# RL6842_IP_SVD register map
Vendor: Realtek
IP svd file
Registers are 32-bit, read-write, reset 0x0 unless marked. A register's access mark holds for its fields unless they carry their own. Offsets are from the block's base; lines under a group give offsets from that group; [hi:lo] are bit positions; {n}, {i} and the like mark numbered series; 'fields as' and 'values as' point back to an identical list; <NAME> marks a mode.

## Memory map
0x40000000 page0 size 0x100
0x40000000 page1 size 0x1200
0x40000000 page2 size 0x300
0x40000000 page3 size 0x1310
0x40000000 page4 size 0x14A4
0x40000000 page5 size 0x15AC
0x40000000 page6 size 0x1700
0x40000000 page7 size 0x800
0x40000000 page12 size 0x1300
0x40000000 page17 size 0x1800
0x40000000 page26 size 0x2620
0x40000000 txpwr_ctrl size 0xDB04
0x40100000 RSIP size 0x160
0x40100000 ipsec size 0x101C
0x40108000 hash size 0x101C
0x40118000 spi size 0xB0C
0x4011A000 i2c size 0x100
0x4011C000 SPORT size 0x984
0x4011E000 debugtimer size 0x18
0x4011F000 ECDSA size 0x204
0x41000000 otpc size 0x44
0x41000000 otpc_sec size 0x744
0x4100C000 lp_aon size 0x100
0x4100C100 regu size 0x80
0x4100C200 lp_sys size 0x100
0x4100C300 lp_pmc size 0x64
0x4100C400 xtal size 0x40
0x4100C440 pll size 0x38
0x4100C480 wlafe size 0x40
0x4100C600 memx size 0x200
0x4100CC00 iwdg size 0x14
0x4100F000 uartirda size 0x60
0x41014000 loguart size 0x78
0x41015000 ledc size 0xF8
0x41017000 audio size 0x908
0x41019000 timerpwm size 0x88
0x4101A000 gpio size 0x100
0x4101B000 rtc size 0x2C
0x4101C000 adc size 0xB4
0x4101C800 comp size 0x58
0x4101D000 thermal size 0x34
0x4101E000 captouch size 0x418
0x41020000 ipc size 0x28
0x41022100 aud size 0x30
0x42001C00 zgb size 0x28

## debugtimer
Base 0x4011E000
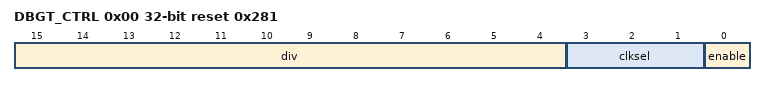
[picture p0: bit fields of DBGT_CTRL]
0x00 DBGT_CTRL reset 0x281 — debugtimer control register
  [15:4] div — The default value can used to divide 40M XTAL to 1M
  [3:1] clksel — Clock source selection 2~7: Reserved 1: Select 32K as clock source. 0: Select Xtal as clock source.
  [0] enable — Debug timer enable 1: The counter is enabled. 0: The counter is disabled.
0x04 DBGT_CRV — debugtimer count register
  [31:0] dbgt_crv — Continue to count from 0 once it's reached 32'hFFFFFFFF
0x08 DBGT_ATOM_INC ro — debugtimer atom read increase register
  [31:0] dbgt_atom_inc — Each read will increase 1 and return to the increased value to bus.
0x0C DBGT_ATOM — debugtimer atom register
  [31:0] dbgt_atom — Return the last increased value of atom counter
0x10 DBGT_SCRATCH — debugtimer scratch register
  [31:0] dbgt_scratch — Reserved for users
0x14 REG_DBGTIM_DUMMY reset 0xFFFF — Debug Timer Dummy Register

## iwdg
Base 0x4100CC00
0x00 WDG_MKEYR — WDG Magic Key Register
  [15:0] MKEY — 0x6969: enable access to register WDG_CR/WDG_RLR/WDG_WINR 0x5A5A: reload WDG counter 0x3C3C: enable WDG function
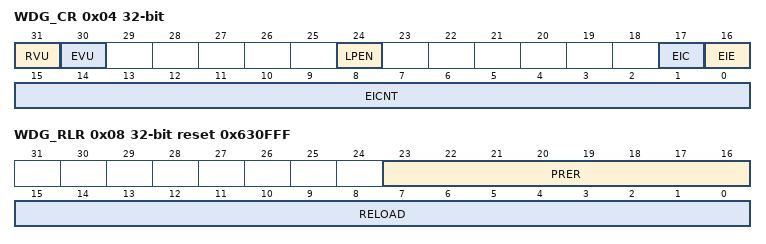
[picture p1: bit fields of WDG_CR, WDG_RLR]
0x04 WDG_CR access per field — WDG Control Regsietr
  [31] RVU ro — Watchdog counter update by reload command
  [30] EVU ro — Watchdog early interrupt function update
  [24] LPEN rw — Low power enable 0: WDG will be gating when system goes into sleep mode 1: WDG keeps running when system goes into sleep mode
  [17] EIC wo — Write '1' clear the early interrupt
  [16] EIE rw — Watchdog early interrupt enable
  [15:0] EICNT rw — Early interrupt trigger threshold
0x08 WDG_RLR reset 0x630FFF — WDG Reload Register
  [23:16] PRER — Prescaler counter, configuration only allowed before watchdog enable WDG: 0x63 System WDG: 0x1F
  [15:0] RELOAD — Reload value for watchdog counter
0x0C WDG_WINR reset 0xFFFF — WDG Window Register
  [15:0] WINDOW — Watchdog feed protect window register
0x10 IWDG_DUMMY reset 0xFF — Dummy Register
  [15:0] dummy — Hardware dummy

## page26
Base 0x40000000
0x2600 TWT_BC_ID — TWT IE ID BITMAP
  [31:0] r_BC_TWT_ID — TWT ID bitmap, each bit corresponding to a ID value
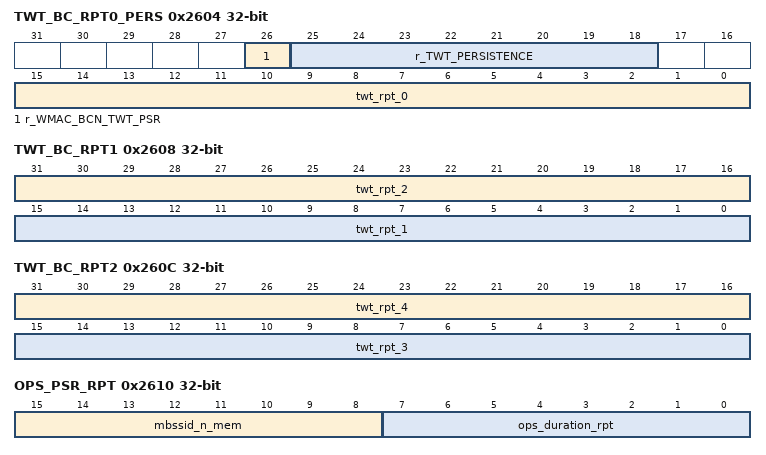
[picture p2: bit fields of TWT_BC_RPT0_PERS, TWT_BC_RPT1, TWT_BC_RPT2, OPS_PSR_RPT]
0x2604 TWT_BC_RPT0_PERS — TWT IE persistence reference and RPT0
  [26] r_WMAC_BCN_TWT_PSR — enable bcn twt bc ie parser
  [25:18] r_TWT_PERSISTENCE — persistence vlaue, if persistence value in TWT IE is smaller than the reference, bcnpsf will lat the twt id rpt
  [15:0] twt_rpt_0 — specified twt id report
0x2608 TWT_BC_RPT1 — TWT IE ID RPT1
  [31:16] twt_rpt_2 — specified twt id report
  [15:0] twt_rpt_1 — specified twt id report
0x260C TWT_BC_RPT2 — TWT IE ID RPT2
  [31:16] twt_rpt_4 — specified twt id report
  [15:0] twt_rpt_3 — specified twt id report
0x2610 OPS_PSR_RPT — OPS DURATION
  [15:8] mbssid_n_mem — multi-bssid n value
  [7:0] ops_duration_rpt — ops frame duration field rpt
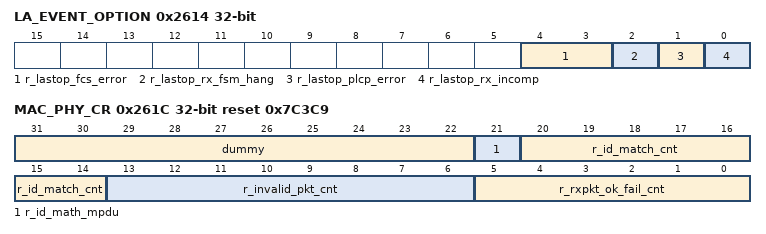
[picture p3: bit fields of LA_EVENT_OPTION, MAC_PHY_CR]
0x2614 LA_EVENT_OPTION
  [4:3] r_lastop_fcs_error — stop LA record when continue fcs error >= threshold 0:disable 1:4 2:8 3:12
  [2] r_lastop_rx_fsm_hang — stop LA record when RX FSM timeout
  [1] r_lastop_plcp_error — stop LA record when RX PLCP error occur, include Length error, parity error or crc error
  [0] r_lastop_rx_incomp — stop LA record when RX content is incompleted, include PLCP is incompleted or PSDU is incompleted
0x2618 RESP_AID_11 — aid 11 for resp
  [10:0] aid11 — specified the aid of the sta that mactx responding to
0x261C MAC_PHY_CR reset 0x7C3C9 — mac phy control reg
  [31:22] dummy
  [21] r_id_math_mpdu — when set, per mpdu will trigger rx_id_match, else per ppdu trigger rx_id_match
  [20:14] r_id_match_cnt — rxpkt_ok or rxpkt_fail pulse counter,unit 25ns when mac clock is 40MHz
  [13:6] r_invalid_pkt_cnt — invalid_pkt pulse counter,unit 25ns when mac clock is 40MHz
  [5:0] r_rxpkt_ok_fail_cnt — rxpkt_ok or rxpkt_fail pulse counter,unit 25ns when mac clock is 40MHz

## Notices in the file
Copyright (C) 2012-2025 Realsil Limited. All rights reserved.
